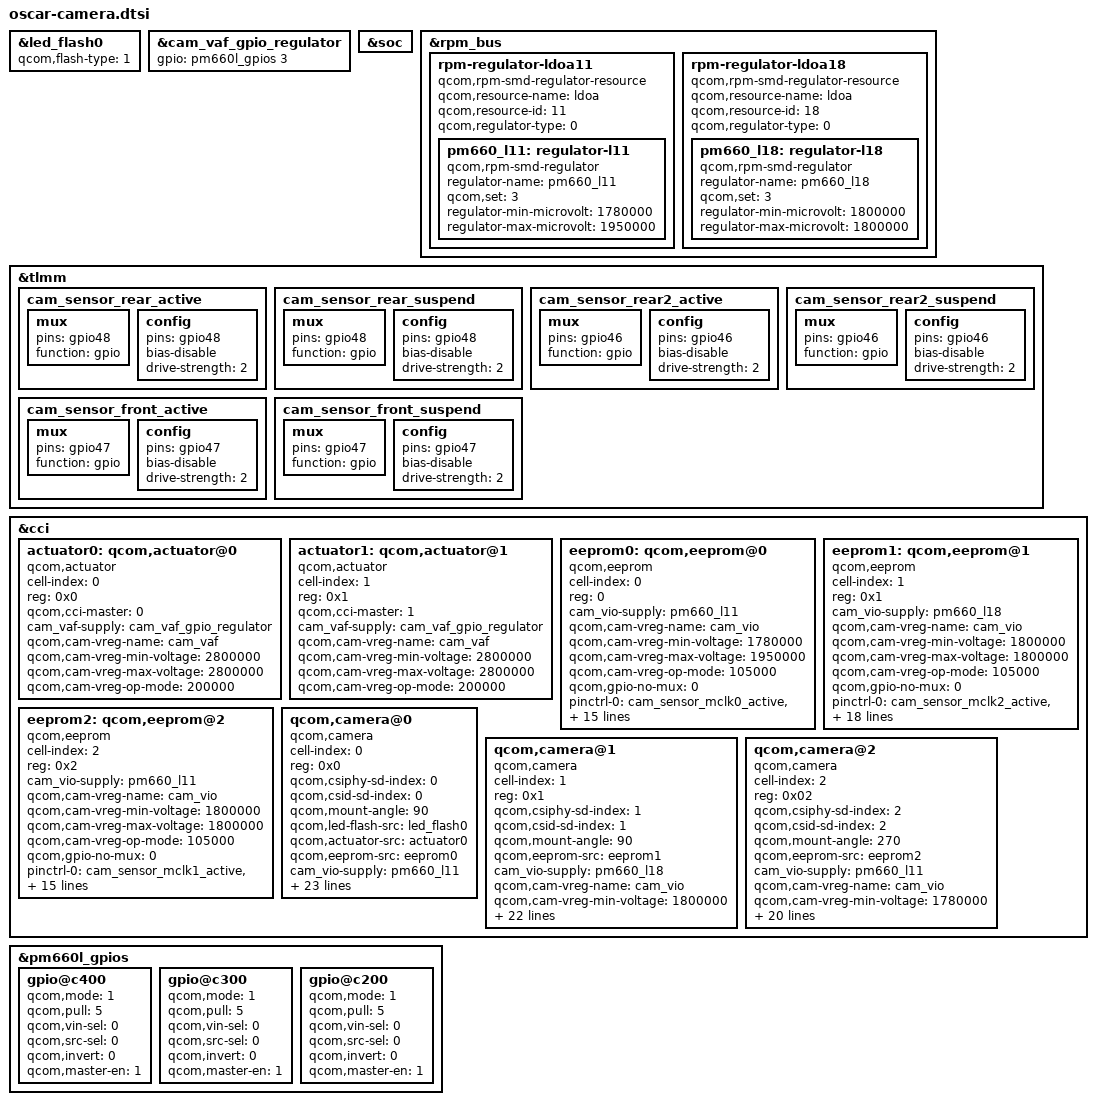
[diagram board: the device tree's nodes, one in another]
/*
 * Copyright (c) 2017, The Linux Foundation. All rights reserved.
 *
 * This program is free software; you can redistribute it and/or modify
 * it under the terms of the GNU General Public License version 2 and
 * only version 2 as published by the Free Software Foundation.
 *
 * This program is distributed in the hope that it will be useful,
 * but WITHOUT ANY WARRANTY; without even the implied warranty of
 * MERCHANTABILITY or FITNESS FOR A PARTICULAR PURPOSE.  See the
 * GNU General Public License for more details.
 */

&led_flash0 {
	qcom,flash-type = <1>;
};

&cam_vaf_gpio_regulator {
	gpio = <&pm660l_gpios 3 0>;
};

&soc {
	/delete-node/ cam_avdd_gpio_regulator;
	/delete-node/ cam_rear_dvdd_gpio_regulator;
};

&rpm_bus {
	rpm-regulator-ldoa11 {
		compatible = "qcom,rpm-smd-regulator-resource";
		qcom,resource-name = "ldoa";
		qcom,resource-id = <11>;
		qcom,regulator-type = <0>;
		status = "okay";
		pm660_l11: regulator-l11 {
			compatible = "qcom,rpm-smd-regulator";
			regulator-name = "pm660_l11";
			qcom,set = <3>;
			regulator-min-microvolt = <1780000>;
			regulator-max-microvolt = <1950000>;
			status = "okay";
		};
	};

	rpm-regulator-ldoa18 {
		compatible = "qcom,rpm-smd-regulator-resource";
		qcom,resource-name = "ldoa";
		qcom,resource-id = <18>;
		qcom,regulator-type = <0>;
		status = "okay";
		pm660_l18: regulator-l18 {
			compatible = "qcom,rpm-smd-regulator";
			regulator-name = "pm660_l18";
			qcom,set = <3>;
			regulator-min-microvolt = <1800000>;
			regulator-max-microvolt = <1800000>;
			status = "okay";
		};
	};
};

&tlmm {
	cam_sensor_rear_active: cam_sensor_rear_active {
		/* RESET */
		mux {
			pins = "gpio48";
			function = "gpio";
		};

		config {
			pins = "gpio48";
			bias-disable; /* No PULL */
			drive-strength = <2>; /* 2 MA */
		};
	};

	cam_sensor_rear_suspend: cam_sensor_rear_suspend {
		/* RESET */
		mux {
			pins = "gpio48";
			function = "gpio";
		};

		config {
			pins = "gpio48";
			bias-disable; /* No PULL */
			drive-strength = <2>; /* 2 MA */
		};
	};

	cam_sensor_rear2_active: cam_sensor_rear2_active {
		/* RESET */
		mux {
			pins = "gpio46";
			function = "gpio";
		};

		config {
			pins = "gpio46";
			bias-disable; /* No PULL */
			drive-strength = <2>; /* 2 MA */
		};
	};

	cam_sensor_rear2_suspend: cam_sensor_rear2_suspend {
		/* RESET */
		mux {
			pins = "gpio46";
			function = "gpio";
		};

		config {
			pins = "gpio46";
			bias-disable; /* No PULL */
			drive-strength = <2>; /* 2 MA */
		};
	};

	cam_sensor_front_active: cam_sensor_front_active {
		/* RESET */
		mux {
			pins = "gpio47";
			function = "gpio";
		};

		config {
			pins = "gpio47";
			bias-disable; /* No PULL */
			drive-strength = <2>; /* 2 MA */
		};
	};

	cam_sensor_front_suspend: cam_sensor_front_suspend {
		/* RESET */
		mux {
			pins = "gpio47";
			function = "gpio";
		};

		config {
			pins = "gpio47";
			bias-disable; /* No PULL */
			drive-strength = <2>; /* 2 MA */
		};
	};
};

&cci {
	actuator0: qcom,actuator@0 {
		cell-index = <0>;
		reg = <0x0>;
		compatible = "qcom,actuator";
		qcom,cci-master = <0>;
		cam_vaf-supply = <&cam_vaf_gpio_regulator>;
		qcom,cam-vreg-name = "cam_vaf";
		qcom,cam-vreg-min-voltage = <2800000>;
		qcom,cam-vreg-max-voltage = <2800000>;
		qcom,cam-vreg-op-mode = <200000>;
	};

	actuator1: qcom,actuator@1 {
		cell-index = <1>;
		reg = <0x1>;
		compatible = "qcom,actuator";
		qcom,cci-master = <1>;
		cam_vaf-supply = <&cam_vaf_gpio_regulator>;
		qcom,cam-vreg-name = "cam_vaf";
		qcom,cam-vreg-min-voltage = <2800000>;
		qcom,cam-vreg-max-voltage = <2800000>;
		qcom,cam-vreg-op-mode = <200000>;
	};

	eeprom0: qcom,eeprom@0 {
		cell-index = <0>;
		reg = <0>;
		compatible = "qcom,eeprom";
		cam_vio-supply = <&pm660_l11>;
		qcom,cam-vreg-name = "cam_vio";
		qcom,cam-vreg-min-voltage = <1780000>;
		qcom,cam-vreg-max-voltage = <1950000>;
		qcom,cam-vreg-op-mode = <105000>;
		qcom,gpio-no-mux = <0>;
		pinctrl-names = "cam_default", "cam_suspend";
		pinctrl-0 = <&cam_sensor_mclk0_active
				&cam_sensor_rear_active>;
		pinctrl-1 = <&cam_sensor_mclk0_suspend
				&cam_sensor_rear_suspend>;
		gpios = <&tlmm 32 0>,
			<&tlmm 48 0>;
		qcom,gpio-reset = <1>;
		qcom,gpio-req-tbl-num = <0 1>;
		qcom,gpio-req-tbl-flags = <1 0>;
		qcom,gpio-req-tbl-label = "CAMIF_MCLK0",
					"CAM_RESET0";
		qcom,sensor-position = <0>;
		qcom,sensor-mode = <0>;
		qcom,cci-master = <0>;
		status = "ok";
		clocks = <&clock_mmss MCLK0_CLK_SRC>,
				<&clock_mmss MMSS_CAMSS_MCLK0_CLK>;
		clock-names = "cam_src_clk", "cam_clk";
		qcom,clock-rates = <24000000 0>;
	};

	eeprom1: qcom,eeprom@1 {
		cell-index = <1>;
		reg = <0x1>;
		compatible = "qcom,eeprom";
		cam_vio-supply = <&pm660_l18>;
		qcom,cam-vreg-name = "cam_vio";
		qcom,cam-vreg-min-voltage = <1800000>;
		qcom,cam-vreg-max-voltage = <1800000>;
		qcom,cam-vreg-op-mode = <105000>;
		qcom,gpio-no-mux = <0>;
		pinctrl-names = "cam_default", "cam_suspend";
		pinctrl-0 = <&cam_sensor_mclk2_active
				 &cam_sensor_rear2_active>;
		pinctrl-1 = <&cam_sensor_mclk2_suspend
				 &cam_sensor_rear2_suspend>;
		gpios = <&tlmm 35 0>,
			<&tlmm 46 0>,
			<&tlmm 51 0>,
			<&pm660l_gpios 5 0>;
		qcom,gpio-reset = <1>;
		qcom,gpio-vana = <2>;
		qcom,gpio-vdig = <3>;
		qcom,gpio-req-tbl-num = <0 1 2 3>;
		qcom,gpio-req-tbl-flags = <1 0 0 0>;
		qcom,gpio-req-tbl-label = "CAMIF_MCLK3",
					  "CAM_RESET1",
					  "CAM_VANA",
					  "CAM_VDIG";
		qcom,sensor-position = <0>;
		qcom,sensor-mode = <0>;
		qcom,cci-master = <1>;
		status = "ok";
		clocks = <&clock_mmss MCLK3_CLK_SRC>,
		    <&clock_mmss MMSS_CAMSS_MCLK3_CLK>;
		clock-names = "cam_src_clk", "cam_clk";
		qcom,clock-rates = <24000000 0>;
	};

	eeprom2: qcom,eeprom@2 {
		cell-index = <2>;
		reg = <0x2>;
		compatible = "qcom,eeprom";
		cam_vio-supply = <&pm660_l11>;
		qcom,cam-vreg-name = "cam_vio";
		qcom,cam-vreg-min-voltage = <1800000>;
		qcom,cam-vreg-max-voltage = <1800000>;
		qcom,cam-vreg-op-mode = <105000>;
		qcom,gpio-no-mux = <0>;
		pinctrl-names = "cam_default", "cam_suspend";
		pinctrl-0 = <&cam_sensor_mclk1_active
				 &cam_sensor_front_active>;
		pinctrl-1 = <&cam_sensor_mclk1_suspend
				 &cam_sensor_front_suspend>;
		gpios = <&tlmm 33 0>,
			<&tlmm 47 0>;
		qcom,gpio-reset = <1>;
		qcom,gpio-req-tbl-num = <0 1>;
		qcom,gpio-req-tbl-flags = <1 0>;
		qcom,gpio-req-tbl-label = "CAMIF_MCLK2",
					"CAM_RESET2";
		qcom,sensor-position = <1>;
		qcom,sensor-mode = <0>;
		qcom,cci-master = <1>;
		status = "ok";
		clocks = <&clock_mmss MCLK1_CLK_SRC>,
			<&clock_mmss MMSS_CAMSS_MCLK1_CLK>;
		clock-names = "cam_src_clk", "cam_clk";
		qcom,clock-rates = <24000000 0>;
	};

	qcom,camera@0 {
		cell-index = <0>;
		compatible = "qcom,camera";
		reg = <0x0>;
		qcom,csiphy-sd-index = <0>;
		qcom,csid-sd-index = <0>;
		qcom,mount-angle = <90>;
		qcom,led-flash-src = <&led_flash0>;
		qcom,actuator-src = <&actuator0>;
		qcom,eeprom-src = <&eeprom0>;
		cam_vio-supply = <&pm660_l11>;
		cam_v_custom2-supply = <&pm660l_l3>;
		qcom,cam-vreg-name = "cam_vio", "cam_v_custom2";
		qcom,cam-vreg-min-voltage = <1780000 2800000>;
		qcom,cam-vreg-max-voltage = <1950000 2800000>;
		qcom,cam-vreg-op-mode = <105000 0>;
		qcom,gpio-no-mux = <0>;
		pinctrl-names = "cam_default", "cam_suspend";
		pinctrl-0 = <&cam_sensor_mclk0_active
				 &cam_sensor_rear_active>;
		pinctrl-1 = <&cam_sensor_mclk0_suspend
				 &cam_sensor_rear_suspend>;
		gpios = <&tlmm 32 0>,
			<&tlmm 48 0>,
			<&pm660l_gpios 4 0>;
		qcom,gpio-reset = <1>;
		qcom,gpio-vdig = <2>;
		qcom,gpio-req-tbl-num = <0 1 2>;
		qcom,gpio-req-tbl-flags = <1 0 0>;
		qcom,gpio-req-tbl-label = "CAMIF_MCLK0",
					"CAM_RESET0",
					"CAM_VDIG";
		qcom,sensor-position = <0>;
		qcom,sensor-mode = <0>;
		qcom,cci-master = <0>;
		status = "ok";
		clocks = <&clock_mmss MCLK0_CLK_SRC>,
				<&clock_mmss MMSS_CAMSS_MCLK0_CLK>;
		clock-names = "cam_src_clk", "cam_clk";
		qcom,clock-rates = <24000000 0>;
	};

	qcom,camera@1 {
		cell-index = <1>;
		compatible = "qcom,camera";
		reg = <0x1>;
		qcom,csiphy-sd-index = <1>;
		qcom,csid-sd-index = <1>;
		qcom,mount-angle = <90>;
		qcom,eeprom-src = <&eeprom1>;
		cam_vio-supply = <&pm660_l18>;
		qcom,cam-vreg-name = "cam_vio";
		qcom,cam-vreg-min-voltage = <1800000>;
		qcom,cam-vreg-max-voltage = <1800000>;
		qcom,cam-vreg-op-mode = <105000>;
		qcom,gpio-no-mux = <0>;
		pinctrl-names = "cam_default", "cam_suspend";
		pinctrl-0 = <&cam_sensor_mclk2_active
				 &cam_sensor_rear2_active>;
		pinctrl-1 = <&cam_sensor_mclk2_suspend
				 &cam_sensor_rear2_suspend>;
		gpios = <&tlmm 35 0>,
			<&tlmm 46 0>,
			<&tlmm 51 0>,
			<&pm660l_gpios 5 0>;
		qcom,gpio-reset = <1>;
		qcom,gpio-vana = <2>;
		qcom,gpio-vdig = <3>;
		qcom,gpio-req-tbl-num = <0 1 2 3>;
		qcom,gpio-req-tbl-flags = <1 0 0 0>;
		qcom,gpio-req-tbl-label = "CAMIF_MCLK3",
					  "CAM_RESET1",
					  "CAM_VANA",
					  "CAM_VDIG";
		qcom,sensor-position = <0>;
		qcom,sensor-mode = <0>;
		qcom,cci-master = <1>;
		status = "ok";
		clocks = <&clock_mmss MCLK3_CLK_SRC>,
			<&clock_mmss MMSS_CAMSS_MCLK3_CLK>;
		clock-names = "cam_src_clk", "cam_clk";
		qcom,clock-rates = <24000000 0>;
	};

	qcom,camera@2 {
		cell-index = <2>;
		compatible = "qcom,camera";
		reg = <0x02>;
		qcom,csiphy-sd-index = <2>;
		qcom,csid-sd-index = <2>;
		qcom,mount-angle = <270>;
		qcom,eeprom-src = <&eeprom2>;
		cam_vio-supply = <&pm660_l11>;
		qcom,cam-vreg-name = "cam_vio";
		qcom,cam-vreg-min-voltage = <1780000>;
		qcom,cam-vreg-max-voltage = <1950000>;
		qcom,cam-vreg-op-mode = <105000>;
		qcom,gpio-no-mux = <0>;
		pinctrl-names = "cam_default", "cam_suspend";
		pinctrl-0 = <&cam_sensor_mclk1_active
				 &cam_sensor_front_active>;
		pinctrl-1 = <&cam_sensor_mclk1_suspend
				 &cam_sensor_front_suspend>;
		gpios = <&tlmm 33 0>,
			<&tlmm 47 0>,
			<&tlmm 50 0>;
		qcom,gpio-reset = <1>;
		qcom,gpio-vdig = <2>;
		qcom,gpio-req-tbl-num = <0 1 2>;
		qcom,gpio-req-tbl-flags = <1 0 0>;
		qcom,gpio-req-tbl-label = "CAMIF_MCLK2",
					"CAM_RESET2",
					"CAM_VDIG";
		qcom,sensor-position = <1>;
		qcom,sensor-mode = <0>;
		qcom,cci-master = <1>;
		status = "ok";
		clocks = <&clock_mmss MCLK1_CLK_SRC>,
			<&clock_mmss MMSS_CAMSS_MCLK1_CLK>;
		clock-names = "cam_src_clk", "cam_clk";
		qcom,clock-rates = <24000000 0>;
	};
};

&pm660l_gpios {
	gpio@c400 { /* GPIO5 -CAMERA SENSOR 1 VDIG*/
		qcom,mode = <1>;                /* Output */
		qcom,pull = <5>;                /* No Pull */
		qcom,vin-sel = <0>;             /* VIN1 GPIO_LV */
		qcom,src-sel = <0>;             /* GPIO */
		qcom,invert = <0>;              /* Invert */
		qcom,master-en = <1>;           /* Enable GPIO */
		status = "ok";
	};

	gpio@c300 { /* GPIO4 -CAMERA SENSOR 0 VDIG*/
		qcom,mode = <1>;                /* Output */
		qcom,pull = <5>;                /* No Pull */
		qcom,vin-sel = <0>;             /* VIN1 GPIO_LV */
		qcom,src-sel = <0>;             /* GPIO */
		qcom,invert = <0>;              /* Invert */
		qcom,master-en = <1>;           /* Enable GPIO */
		status = "ok";
	};

	gpio@c200 { /* GPIO3 -CAMERA SENSOR 2 VDIG*/
		qcom,mode = <1>;                /* Output */
		qcom,pull = <5>;                /* No Pull */
		qcom,vin-sel = <0>;             /* VIN1 GPIO_LV */
		qcom,src-sel = <0>;             /* GPIO */
		qcom,invert = <0>;              /* Invert */
		qcom,master-en = <1>;           /* Enable GPIO */
		status = "ok";
	};
};
